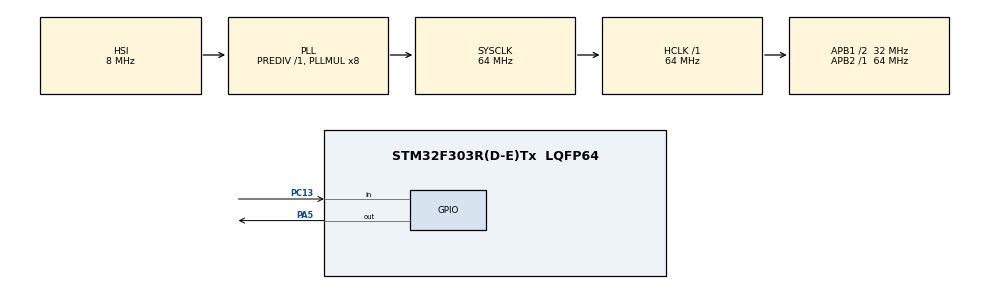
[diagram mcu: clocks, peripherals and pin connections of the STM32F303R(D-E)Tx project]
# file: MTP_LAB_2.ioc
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Mcu.Family=STM32F3
Mcu.Name=STM32F303R(D-E)Tx
Mcu.Package=LQFP64
NVIC.PriorityGroup=NVIC_PRIORITYGROUP_4
PA13.Mode=Serial_Wire
PA13.Signal=SYS_JTMS-SWDIO
PA14.Mode=Serial_Wire
PA14.Signal=SYS_JTCK-SWCLK
PA5.Signal=GPIO_Output
PC13.GPIO_PuPd=GPIO_PULLUP
PC13.Signal=GPIO_Input
ProjectManager.HeapSize=0x200
ProjectManager.StackSize=0x400
ProjectManager.TargetToolchain=STM32CubeIDE
RCC.AHBFreq_Value=64000000
RCC.APB1CLKDivider=RCC_HCLK_DIV2
RCC.APB1Freq_Value=32000000
RCC.APB1TimFreq_Value=64000000
RCC.APB2Freq_Value=64000000
RCC.APB2TimFreq_Value=64000000
RCC.CortexFreq_Value=64000000
RCC.HCLKFreq_Value=64000000
RCC.HSE_VALUE=8000000
RCC.HSI_VALUE=8000000
RCC.LSE_VALUE=32768
RCC.PLLMUL=RCC_PLL_MUL8
RCC.SYSCLKFreq_VALUE=64000000
RCC.SYSCLKSourceVirtual=RCC_SYSCLKSOURCE_PLLCLK
RCC.USBFreq_Value=64000000
board=custom

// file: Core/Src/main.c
/* USER CODE BEGIN Header */
/**
  ******************************************************************************
  * @file           : main.c
  * @brief          : Main program body
  ******************************************************************************
  * @attention
  *
  * <h2><center>&copy; Copyright (c) 2021 STMicroelectronics.
  * All rights reserved.</center></h2>
  *
  * This software component is licensed by ST under BSD 3-Clause license,
  * the "License"; You may not use this file except in compliance with the
  * License. You may obtain a copy of the License at:
  *                        opensource.org/licenses/BSD-3-Clause
  *
  ******************************************************************************
  */
/* USER CODE END Header */

#include "main.h"

void SystemClock_Config(void);
static void MX_GPIO_Init(void);
/* USER CODE BEGIN PFP */

void vysliCiarku(void);
void vysliBodku(void);
void vysliMedzeru(void);
/* USER CODE END PFP */

/* USER CODE BEGIN 0 */

// Cely projekt sa nachadza na githube: https://github.com/gkaretka/MTP/tree/main/MTP_LAB_2
#define ONE_SPACE		250

#define BODKA '.'
#define BODKA_DELAY		ONE_SPACE

#define CIARKA '-'
#define CIARKA_DELAY	(ONE_SPACE*3)

#define MEDZERA '/'
#define MEDZERA_DELAY	(ONE_SPACE*3)

char msg[] = ".../---/...//";
/* USER CODE END 0 */

int main(void)
{
  /* USER CODE BEGIN 1 */
  uint8_t lock = 0;
  /* USER CODE END 1 */

  /* MCU Configuration--------------------------------------------------------*/

  /* Reset of all peripherals, Initializes the Flash interface and the Systick. */
  HAL_Init();

  /* Configure the system clock */
  SystemClock_Config();

  /* Initialize all configured peripherals */
  MX_GPIO_Init();

  /* Infinite loop */
  /* USER CODE BEGIN WHILE */
  while (1)
  {
	if (HAL_GPIO_ReadPin(GPIOC, GPIO_PIN_13) == 0 && !lock)
	{
		lock = 1;
		char *msg_ptr = msg;
		while(*msg_ptr != '\0') {
			if (*msg_ptr == BODKA) {
				vysliBodku();
			} else if (*msg_ptr == CIARKA) {
				vysliCiarku();
			} else if (*msg_ptr == MEDZERA) {
				vysliMedzeru();
			}
			msg_ptr++;
		}
		lock = 0;
	}
    /* USER CODE END WHILE */

  }
}

void SystemClock_Config(void)
{
  RCC_OscInitTypeDef RCC_OscInitStruct = {0};
  RCC_ClkInitTypeDef RCC_ClkInitStruct = {0};

  /** Initializes the CPU, AHB and APB busses clocks
  */
  RCC_OscInitStruct.OscillatorType = RCC_OSCILLATORTYPE_HSI;
  RCC_OscInitStruct.HSIState = RCC_HSI_ON;
  RCC_OscInitStruct.HSICalibrationValue = RCC_HSICALIBRATION_DEFAULT;
  RCC_OscInitStruct.PLL.PLLState = RCC_PLL_ON;
  RCC_OscInitStruct.PLL.PLLSource = RCC_PLLSOURCE_HSI;
  RCC_OscInitStruct.PLL.PLLMUL = RCC_PLL_MUL8;
  RCC_OscInitStruct.PLL.PREDIV = RCC_PREDIV_DIV1;
  if (HAL_RCC_OscConfig(&RCC_OscInitStruct) != HAL_OK)
  {
    Error_Handler();
  }
  /** Initializes the CPU, AHB and APB busses clocks
  */
  RCC_ClkInitStruct.ClockType = RCC_CLOCKTYPE_HCLK|RCC_CLOCKTYPE_SYSCLK
                              |RCC_CLOCKTYPE_PCLK1|RCC_CLOCKTYPE_PCLK2;
  RCC_ClkInitStruct.SYSCLKSource = RCC_SYSCLKSOURCE_PLLCLK;
  RCC_ClkInitStruct.AHBCLKDivider = RCC_SYSCLK_DIV1;
  RCC_ClkInitStruct.APB1CLKDivider = RCC_HCLK_DIV2;
  RCC_ClkInitStruct.APB2CLKDivider = RCC_HCLK_DIV1;

  if (HAL_RCC_ClockConfig(&RCC_ClkInitStruct, FLASH_LATENCY_2) != HAL_OK)
  {
    Error_Handler();
  }
}

static void MX_GPIO_Init(void)
{
  GPIO_InitTypeDef GPIO_InitStruct = {0};

  /* GPIO Ports Clock Enable */
  __HAL_RCC_GPIOC_CLK_ENABLE();
  __HAL_RCC_GPIOA_CLK_ENABLE();

  /*Configure GPIO pin Output Level */
  HAL_GPIO_WritePin(GPIOA, GPIO_PIN_5, GPIO_PIN_RESET);

  /*Configure GPIO pin : PC13 */
  GPIO_InitStruct.Pin = GPIO_PIN_13;
  GPIO_InitStruct.Mode = GPIO_MODE_INPUT;
  GPIO_InitStruct.Pull = GPIO_PULLUP;
  HAL_GPIO_Init(GPIOC, &GPIO_InitStruct);

  /*Configure GPIO pin : PA5 */
  GPIO_InitStruct.Pin = GPIO_PIN_5;
  GPIO_InitStruct.Mode = GPIO_MODE_OUTPUT_PP;
  GPIO_InitStruct.Pull = GPIO_NOPULL;
  GPIO_InitStruct.Speed = GPIO_SPEED_FREQ_LOW;
  HAL_GPIO_Init(GPIOA, &GPIO_InitStruct);

}

/* USER CODE BEGIN 4 */
void vysliCiarku(void)
{
	HAL_GPIO_WritePin(GPIOA, GPIO_PIN_5, GPIO_PIN_SET);
	HAL_Delay(CIARKA_DELAY);
	HAL_GPIO_WritePin(GPIOA, GPIO_PIN_5, GPIO_PIN_RESET);
	HAL_Delay(ONE_SPACE);
}

void vysliBodku(void)
{
	HAL_GPIO_WritePin(GPIOA, GPIO_PIN_5, GPIO_PIN_SET);
	HAL_Delay(BODKA_DELAY);
	HAL_GPIO_WritePin(GPIOA, GPIO_PIN_5, GPIO_PIN_RESET);
	HAL_Delay(ONE_SPACE);
}

void vysliMedzeru(void)
{
	HAL_GPIO_WritePin(GPIOA, GPIO_PIN_5, GPIO_PIN_RESET);
	HAL_Delay(MEDZERA_DELAY);
}
/* USER CODE END 4 */

void Error_Handler(void)
{
}

/************************ (C) COPYRIGHT STMicroelectronics *****END OF FILE****/
